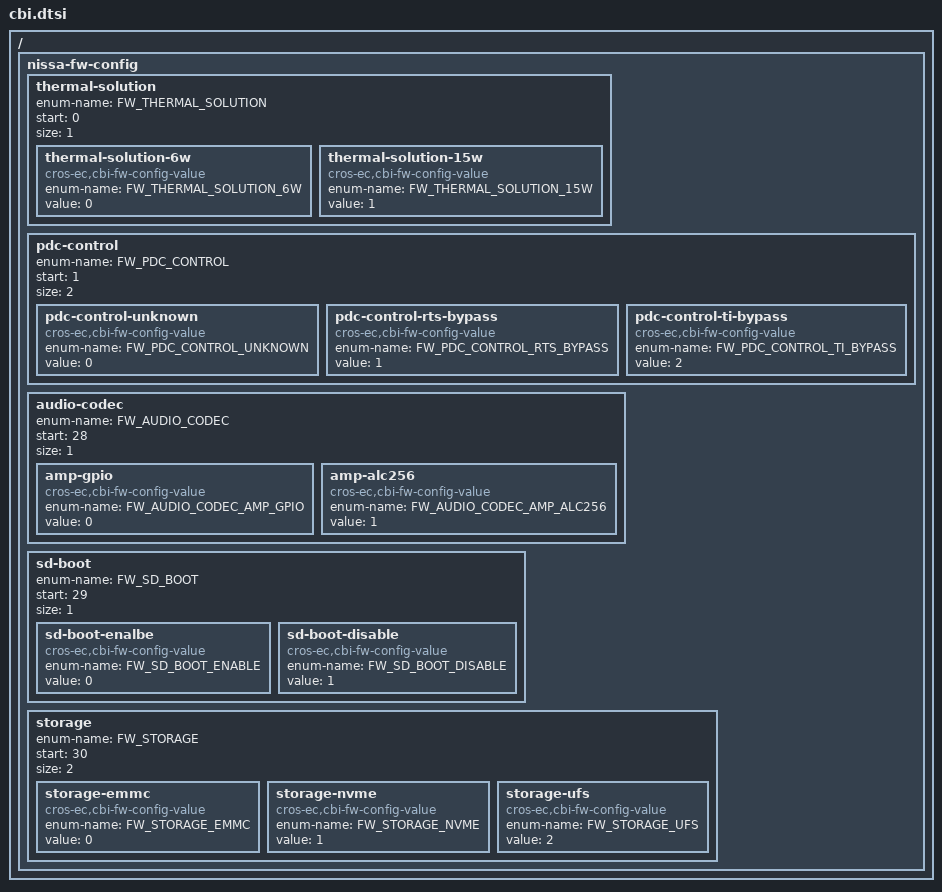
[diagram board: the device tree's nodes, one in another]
/* Copyright 2023 The ChromiumOS Authors
 * Use of this source code is governed by a BSD-style license that can be
 * found in the LICENSE file.
 */

/ {
/* Orisa-specific fw_config fields. */
	nissa-fw-config {
		/*
		 * FW_CONFIG field to defined for THERMAL SOLUTION.
		 */
		thermal-solution {
			enum-name = "FW_THERMAL_SOLUTION";
			start = <0>;
			size = <1>;

			thermal-solution-6w {
				compatible = "cros-ec,cbi-fw-config-value";
				enum-name = "FW_THERMAL_SOLUTION_6W";
				value = <0>;
			};
			thermal-solution-15w {
				compatible = "cros-ec,cbi-fw-config-value";
				enum-name = "FW_THERMAL_SOLUTION_15W";
				value = <1>;
			};
		};

		/*
		 * FW_CONFIG field to defined for pdc control.
		 */
		pdc-control {
			enum-name = "FW_PDC_CONTROL";
			start = <1>;
			size = <2>;

			pdc-control-unknown {
				compatible = "cros-ec,cbi-fw-config-value";
				enum-name = "FW_PDC_CONTROL_UNKNOWN";
				value = <0>;
			};
			pdc-control-rts-bypass {
				compatible = "cros-ec,cbi-fw-config-value";
				enum-name = "FW_PDC_CONTROL_RTS_BYPASS";
				value = <1>;
			};
			pdc-control-ti-bypass {
				compatible = "cros-ec,cbi-fw-config-value";
				enum-name = "FW_PDC_CONTROL_TI_BYPASS";
				value = <2>;
			};
		};

		/*
		 * FW_CONFIG field to defined for audio codec.
		 */
		audio-codec {
			enum-name = "FW_AUDIO_CODEC";
			start = <28>;
			size = <1>;

			amp-gpio {
				compatible = "cros-ec,cbi-fw-config-value";
				enum-name = "FW_AUDIO_CODEC_AMP_GPIO";
				value = <0>;
			};
			amp-alc256 {
				compatible = "cros-ec,cbi-fw-config-value";
				enum-name = "FW_AUDIO_CODEC_AMP_ALC256";
				value = <1>;
			};
		};

		/*
		 * FW_CONFIG field to defined for SD BOOT.
		 */
		sd-boot {
			enum-name = "FW_SD_BOOT";
			start = <29>;
			size = <1>;

			sd-boot-enalbe {
				compatible = "cros-ec,cbi-fw-config-value";
				enum-name = "FW_SD_BOOT_ENABLE";
				value = <0>;
			};
			sd-boot-disable {
				compatible = "cros-ec,cbi-fw-config-value";
				enum-name = "FW_SD_BOOT_DISABLE";
				value = <1>;
			};
		};

		/*
		 * FW_CONFIG field to defined for STORAGE TYPE.
		 */
		storage {
			enum-name = "FW_STORAGE";
			start = <30>;
			size = <2>;

			storage-emmc {
				compatible = "cros-ec,cbi-fw-config-value";
				enum-name = "FW_STORAGE_EMMC";
				value = <0>;
			};
			storage-nvme {
				compatible = "cros-ec,cbi-fw-config-value";
				enum-name = "FW_STORAGE_NVME";
				value = <1>;
			};
			storage-ufs {
				compatible = "cros-ec,cbi-fw-config-value";
				enum-name = "FW_STORAGE_UFS";
				value = <2>;
			};
		};
/delete-node/ fan;
/delete-node/ sub-board;
	};
};
